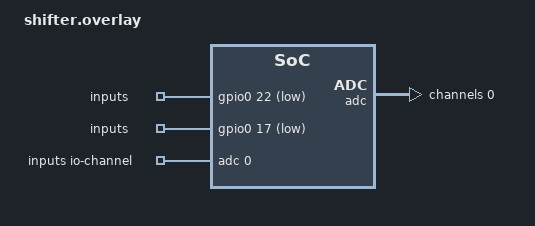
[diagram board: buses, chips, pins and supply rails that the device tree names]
#include "common.overlay"

/ {
	inputs: zephyr,user {
		io-channels = <&adc 0>;
		gpios = <&gpio0 22 (GPIO_ACTIVE_LOW | GPIO_PULL_UP)>,
		        <&gpio0 17 (GPIO_ACTIVE_LOW | GPIO_PULL_UP)>;
	};
};

&adc {
	#address-cells = <1>;
	#size-cells = <0>;
	status = "okay";

	channel@0 {
		reg = <0>;
		zephyr,gain = "ADC_GAIN_1_6";
		zephyr,reference = "ADC_REF_INTERNAL";
		zephyr,acquisition-time = <ADC_ACQ_TIME_DEFAULT>;
		zephyr,input-positive = <NRF_SAADC_AIN7>;  // 0_31
		zephyr,resolution = <12>;
	};
};
